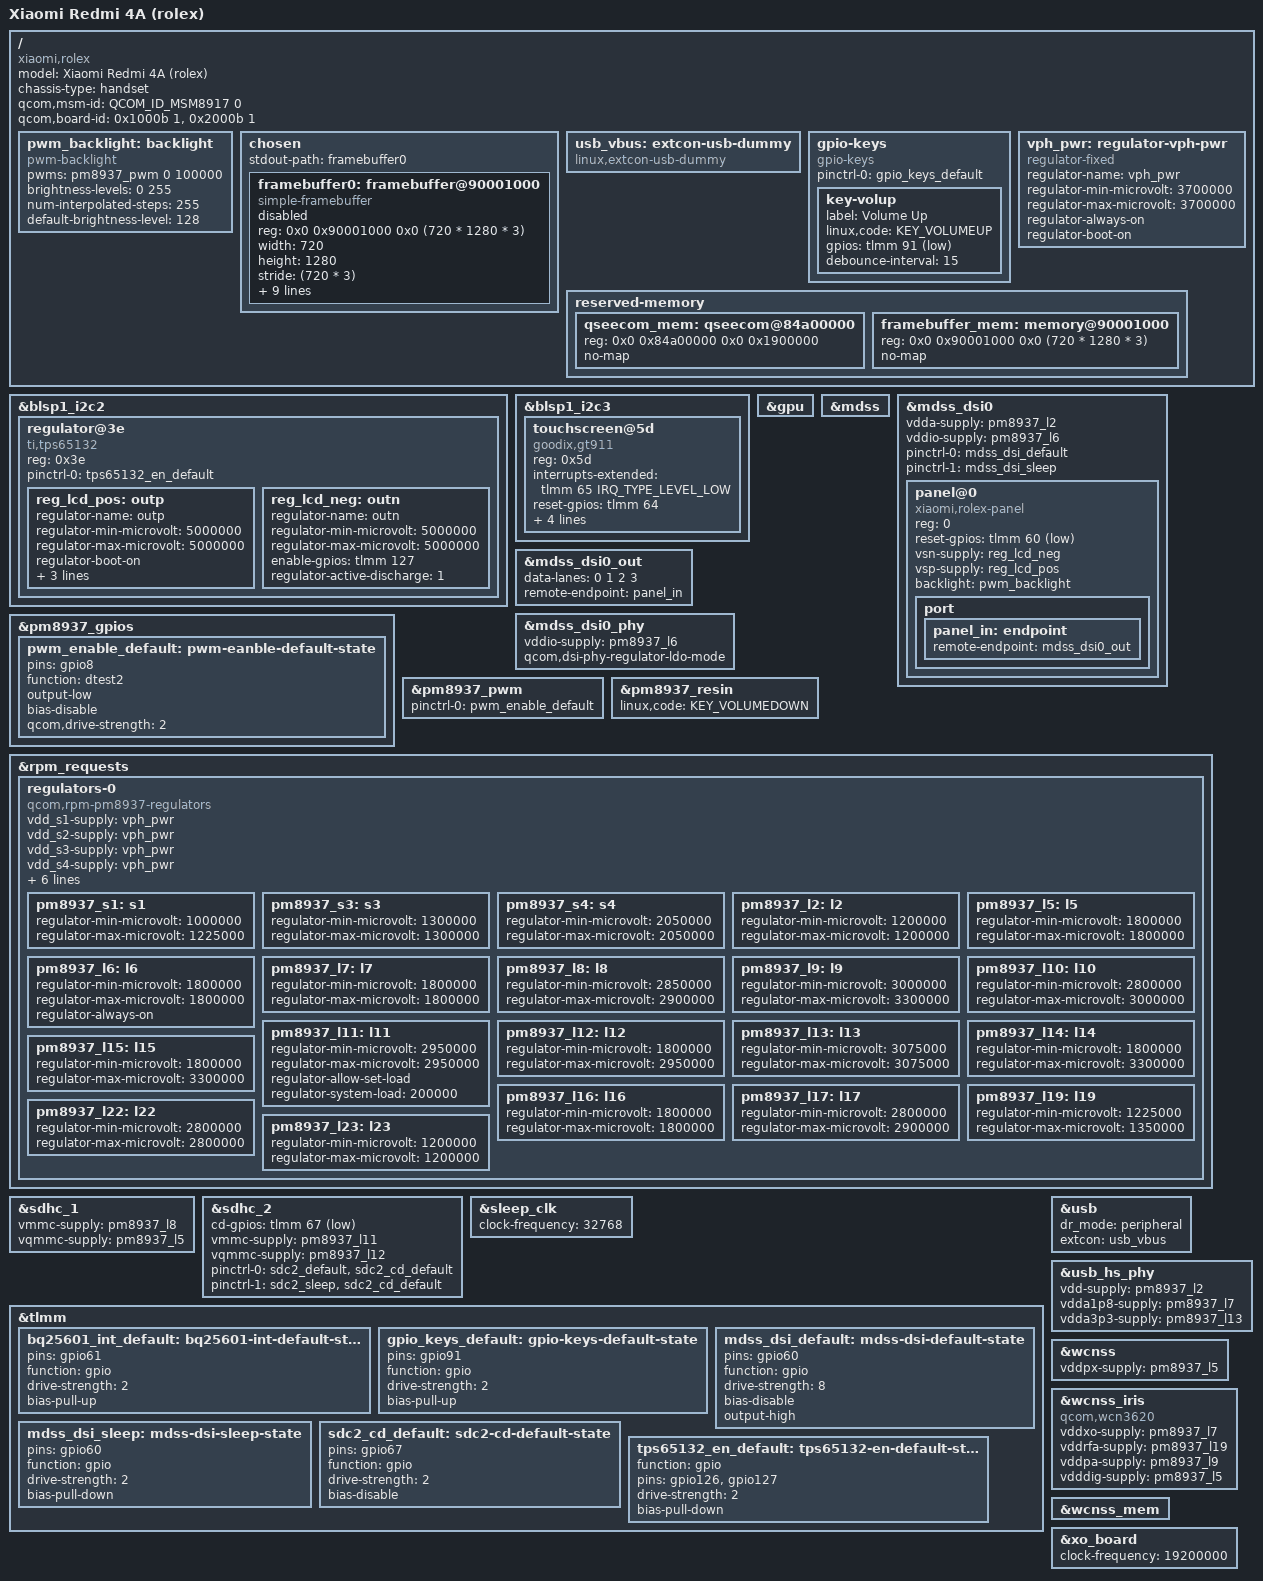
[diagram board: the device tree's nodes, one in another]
// SPDX-License-Identifier: GPL-2.0-only
/*
 * Copyright (c) 2024, Barnabas Czeman
 */

/dts-v1/;

#include <dt-bindings/arm/qcom,ids.h>
#include <dt-bindings/gpio/gpio.h>
#include <dt-bindings/input/linux-event-codes.h>
#include <dt-bindings/leds/common.h>
#include "msm8917.dtsi"
#include "pm8937.dtsi"

/delete-node/ &qseecom_mem;

/ {
	model = "Xiaomi Redmi 4A (rolex)";
	compatible = "xiaomi,rolex", "qcom,msm8917";
	chassis-type = "handset";

	qcom,msm-id = <QCOM_ID_MSM8917 0>;
	qcom,board-id = <0x1000b 1>, <0x2000b 1>;

	pwm_backlight: backlight {
		compatible = "pwm-backlight";
		pwms = <&pm8937_pwm 0 100000>;

		brightness-levels = <0 255>;
		num-interpolated-steps = <255>;
		default-brightness-level = <128>;
	};

	chosen {
		#address-cells = <2>;
		#size-cells = <2>;
		ranges;

		stdout-path = "framebuffer0";

		framebuffer0: framebuffer@90001000 {
			compatible = "simple-framebuffer";
			reg = <0x0 0x90001000 0x0 (720 * 1280 * 3)>;
			width = <720>;
			height = <1280>;
			stride = <(720 * 3)>;
			format = "r8g8b8";

			clocks = <&gcc GCC_MDSS_AHB_CLK>,
				 <&gcc GCC_MDSS_AXI_CLK>,
				 <&gcc GCC_MDSS_VSYNC_CLK>,
				 <&gcc GCC_MDSS_MDP_CLK>,
				 <&gcc GCC_MDSS_BYTE0_CLK>,
				 <&gcc GCC_MDSS_PCLK0_CLK>,
				 <&gcc GCC_MDSS_ESC0_CLK>;
			power-domains = <&gcc MDSS_GDSC>;
			status = "disabled";
		};
	};

	usb_vbus: extcon-usb-dummy {
		compatible = "linux,extcon-usb-dummy";
	};

	gpio-keys {
		compatible = "gpio-keys";

		pinctrl-0 = <&gpio_keys_default>;
		pinctrl-names = "default";

		key-volup {
			label = "Volume Up";
			linux,code = <KEY_VOLUMEUP>;
			gpios = <&tlmm 91 GPIO_ACTIVE_LOW>;
			debounce-interval = <15>;
		};
	};

	vph_pwr: regulator-vph-pwr {
		compatible = "regulator-fixed";
		regulator-name = "vph_pwr";
		regulator-min-microvolt = <3700000>;
		regulator-max-microvolt = <3700000>;
		regulator-always-on;
		regulator-boot-on;
	};

	reserved-memory {
		qseecom_mem: qseecom@84a00000 {
			reg = <0x0 0x84a00000 0x0 0x1900000>;
			no-map;
		};

		framebuffer_mem: memory@90001000 {
			reg = <0x0 0x90001000 0x0 (720 * 1280 * 3)>;
			no-map;
		};
	};
};

&blsp1_i2c2 {
	status = "okay";

	regulator@3e {
		compatible = "ti,tps65132";
		reg = <0x3e>;

		pinctrl-names = "default";
		pinctrl-0 = <&tps65132_en_default>;

		reg_lcd_pos: outp {
			regulator-name = "outp";
			regulator-min-microvolt = <5000000>;
			regulator-max-microvolt = <5000000>;
			regulator-boot-on;
			regulator-always-on;
			enable-gpios = <&tlmm 126 GPIO_ACTIVE_HIGH>;
			regulator-active-discharge = <1>;
		};

		reg_lcd_neg: outn {
			regulator-name = "outn";
			regulator-min-microvolt = <5000000>;
			regulator-max-microvolt = <5000000>;
			enable-gpios = <&tlmm 127 GPIO_ACTIVE_HIGH>;
			regulator-active-discharge = <1>;
		};
	};
};

&blsp1_i2c3 {
	status = "okay";

	touchscreen@5d {
		compatible = "goodix,gt911";
		reg = <0x5d>;
		interrupts-extended = <&tlmm 65 IRQ_TYPE_LEVEL_LOW>;
		reset-gpios = <&tlmm 64 GPIO_ACTIVE_HIGH>;
		AVDD28-supply = <&pm8937_l10>;
		VDDIO-supply = <&pm8937_l5>;

		touchscreen-size-x = <720>;
		touchscreen-size-y = <1280>;
	};
};

&gpu {
	status = "okay";
};

&mdss {
	status = "okay";
};

&mdss_dsi0 {
	vdda-supply = <&pm8937_l2>;
	vddio-supply = <&pm8937_l6>;

	pinctrl-0 = <&mdss_dsi_default>;
	pinctrl-1 = <&mdss_dsi_sleep>;
	pinctrl-names = "default", "sleep";

	panel@0 {
		compatible = "xiaomi,rolex-panel";
		reg = <0>;

		reset-gpios = <&tlmm 60 GPIO_ACTIVE_LOW>;

		vsn-supply = <&reg_lcd_neg>;
		vsp-supply = <&reg_lcd_pos>;

		backlight = <&pwm_backlight>;

		port {
			panel_in: endpoint {
				remote-endpoint = <&mdss_dsi0_out>;
			};
		};
	};
};

&mdss_dsi0_out {
	data-lanes = <0 1 2 3>;
	remote-endpoint = <&panel_in>;
};

&mdss_dsi0_phy {
	vddio-supply = <&pm8937_l6>;
	qcom,dsi-phy-regulator-ldo-mode;
};

&pm8937_gpios {
	pwm_enable_default: pwm-eanble-default-state {
		pins = "gpio8";
		function = "dtest2";
		output-low;
		bias-disable;
		qcom,drive-strength = <2>;
	};
};

&pm8937_pwm {
	pinctrl-0 = <&pwm_enable_default>;
	pinctrl-names = "default";
	status = "okay";
};

&pm8937_resin {
	linux,code = <KEY_VOLUMEDOWN>;

	status = "okay";
};

&rpm_requests {
	regulators-0 {
		compatible = "qcom,rpm-pm8937-regulators";

		vdd_s1-supply = <&vph_pwr>;
		vdd_s2-supply = <&vph_pwr>;
		vdd_s3-supply = <&vph_pwr>;
		vdd_s4-supply = <&vph_pwr>;

		vdd_l1_l19-supply = <&pm8937_s3>;
		vdd_l2_l23-supply = <&pm8937_s3>;
		vdd_l3-supply = <&pm8937_s3>;
		vdd_l4_l5_l6_l7_l16-supply = <&pm8937_s4>;
		vdd_l8_l11_l12_l17_l22-supply = <&vph_pwr>;
		vdd_l9_l10_l13_l14_l15_l18-supply = <&vph_pwr>;

		pm8937_s1: s1 {
			regulator-min-microvolt = <1000000>;
			regulator-max-microvolt = <1225000>;
		};

		pm8937_s3: s3 {
			regulator-min-microvolt = <1300000>;
			regulator-max-microvolt = <1300000>;
		};

		pm8937_s4: s4 {
			regulator-min-microvolt = <2050000>;
			regulator-max-microvolt = <2050000>;
		};

		pm8937_l2: l2 {
			regulator-min-microvolt = <1200000>;
			regulator-max-microvolt = <1200000>;
		};

		pm8937_l5: l5 {
			regulator-min-microvolt = <1800000>;
			regulator-max-microvolt = <1800000>;
		};

		pm8937_l6: l6 {
			regulator-min-microvolt = <1800000>;
			regulator-max-microvolt = <1800000>;
			regulator-always-on;
		};

		pm8937_l7: l7 {
			regulator-min-microvolt = <1800000>;
			regulator-max-microvolt = <1800000>;
		};

		pm8937_l8: l8 {
			regulator-min-microvolt = <2850000>;
			regulator-max-microvolt = <2900000>;
		};

		pm8937_l9: l9 {
			regulator-min-microvolt = <3000000>;
			regulator-max-microvolt = <3300000>;
		};

		pm8937_l10: l10 {
			regulator-min-microvolt = <2800000>;
			regulator-max-microvolt = <3000000>;
		};

		pm8937_l11: l11 {
			regulator-min-microvolt = <2950000>;
			regulator-max-microvolt = <2950000>;
			regulator-allow-set-load;
			regulator-system-load = <200000>;
		};

		pm8937_l12: l12 {
			regulator-min-microvolt = <1800000>;
			regulator-max-microvolt = <2950000>;
		};

		pm8937_l13: l13 {
			regulator-min-microvolt = <3075000>;
			regulator-max-microvolt = <3075000>;
		};

		pm8937_l14: l14 {
			regulator-min-microvolt = <1800000>;
			regulator-max-microvolt = <3300000>;
		};

		pm8937_l15: l15 {
			regulator-min-microvolt = <1800000>;
			regulator-max-microvolt = <3300000>;
		};

		pm8937_l16: l16 {
			regulator-min-microvolt = <1800000>;
			regulator-max-microvolt = <1800000>;
		};

		pm8937_l17: l17 {
			regulator-min-microvolt = <2800000>;
			regulator-max-microvolt = <2900000>;
		};

		pm8937_l19: l19 {
			regulator-min-microvolt = <1225000>;
			regulator-max-microvolt = <1350000>;
		};

		pm8937_l22: l22 {
			regulator-min-microvolt = <2800000>;
			regulator-max-microvolt = <2800000>;
		};

		pm8937_l23: l23 {
			regulator-min-microvolt = <1200000>;
			regulator-max-microvolt = <1200000>;
		};
	};
};

&sdhc_1 {
	vmmc-supply = <&pm8937_l8>;
	vqmmc-supply = <&pm8937_l5>;

	status = "okay";
};

&sdhc_2 {
	cd-gpios = <&tlmm 67 GPIO_ACTIVE_LOW>;
	vmmc-supply = <&pm8937_l11>;
	vqmmc-supply = <&pm8937_l12>;
	pinctrl-0 = <&sdc2_default &sdc2_cd_default>;
	pinctrl-1 = <&sdc2_sleep &sdc2_cd_default>;
	pinctrl-names = "default", "sleep";

	status = "okay";
};

&sleep_clk {
	clock-frequency = <32768>;
};

&tlmm {
	bq25601_int_default: bq25601-int-default-state {
		pins = "gpio61";
		function = "gpio";
		drive-strength = <2>;
		bias-pull-up;
	};

	gpio_keys_default: gpio-keys-default-state {
		pins = "gpio91";
		function = "gpio";
		drive-strength = <2>;
		bias-pull-up;
	};

	mdss_dsi_default: mdss-dsi-default-state {
		pins = "gpio60";
		function = "gpio";
		drive-strength = <8>;
		bias-disable;
		output-high;
	};

	mdss_dsi_sleep: mdss-dsi-sleep-state {
		pins = "gpio60";
		function = "gpio";
		drive-strength = <2>;
		bias-pull-down;
	};

	sdc2_cd_default: sdc2-cd-default-state {
		pins = "gpio67";
		function = "gpio";
		drive-strength = <2>;
		bias-disable;
	};

	tps65132_en_default: tps65132-en-default-state {
		function = "gpio";
		pins = "gpio126", "gpio127";
		drive-strength = <2>;
		bias-pull-down;
	};
};

&usb {
	dr_mode = "peripheral";
	extcon = <&usb_vbus>;
	status = "okay";
};

&usb_hs_phy {
	vdd-supply = <&pm8937_l2>;
	vdda1p8-supply = <&pm8937_l7>;
	vdda3p3-supply = <&pm8937_l13>;
	status = "okay";
};

&wcnss {
	vddpx-supply = <&pm8937_l5>;

	status = "okay";
};

&wcnss_iris {
	compatible = "qcom,wcn3620";
	vddxo-supply = <&pm8937_l7>;
	vddrfa-supply = <&pm8937_l19>;
	vddpa-supply = <&pm8937_l9>;
	vdddig-supply = <&pm8937_l5>;
};

&wcnss_mem {
	status = "okay";
};

&xo_board {
	clock-frequency = <19200000>;
};
